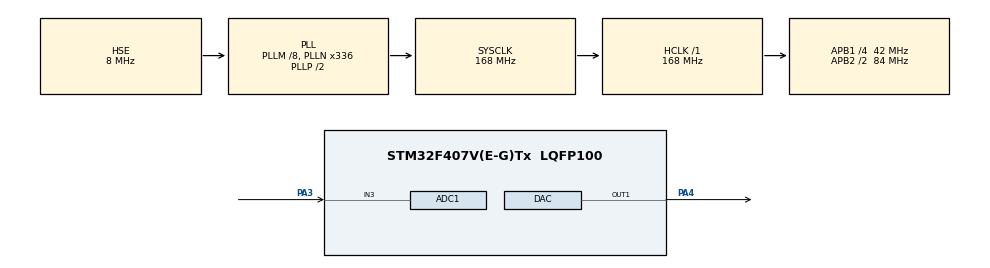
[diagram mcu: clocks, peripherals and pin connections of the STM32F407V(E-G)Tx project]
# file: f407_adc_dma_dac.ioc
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ADC1.Channel-2\#ChannelRegularConversion=ADC_CHANNEL_3
ADC1.ExternalTrigConv=ADC_EXTERNALTRIGCONV_T2_TRGO
ADC1.NbrOfConversionFlag=1
ADC1.Rank-2\#ChannelRegularConversion=1
ADC1.SamplingTime-2\#ChannelRegularConversion=ADC_SAMPLETIME_3CYCLES
ADC1.master=1
DAC.DAC_Trigger=DAC_TRIGGER_T2_TRGO
Dma.ADC1.0.Direction=DMA_PERIPH_TO_MEMORY
Dma.ADC1.0.FIFOMode=DMA_FIFOMODE_DISABLE
Dma.ADC1.0.Instance=DMA2_Stream0
Dma.ADC1.0.MemDataAlignment=DMA_MDATAALIGN_WORD
Dma.ADC1.0.MemInc=DMA_MINC_ENABLE
Dma.ADC1.0.Mode=DMA_CIRCULAR
Dma.ADC1.0.PeriphDataAlignment=DMA_PDATAALIGN_WORD
Dma.ADC1.0.PeriphInc=DMA_PINC_DISABLE
Dma.ADC1.0.Priority=DMA_PRIORITY_HIGH
Dma.DAC1.1.Direction=DMA_MEMORY_TO_PERIPH
Dma.DAC1.1.FIFOMode=DMA_FIFOMODE_DISABLE
Dma.DAC1.1.Instance=DMA1_Stream5
Dma.DAC1.1.MemDataAlignment=DMA_MDATAALIGN_WORD
Dma.DAC1.1.MemInc=DMA_MINC_ENABLE
Dma.DAC1.1.Mode=DMA_CIRCULAR
Dma.DAC1.1.PeriphDataAlignment=DMA_PDATAALIGN_WORD
Dma.DAC1.1.PeriphInc=DMA_PINC_DISABLE
Dma.DAC1.1.Priority=DMA_PRIORITY_LOW
Dma.Request0=ADC1
Dma.Request1=DAC1
Mcu.Family=STM32F4
Mcu.Name=STM32F407V(E-G)Tx
Mcu.Package=LQFP100
NVIC.DMA1_Stream5_IRQn=true\:0\:0\:false\:false\:true\:false\:true
NVIC.DMA2_Stream0_IRQn=true\:0\:0\:false\:false\:true\:false\:true
NVIC.PriorityGroup=NVIC_PRIORITYGROUP_4
PA13.Mode=Serial_Wire
PA13.Signal=SYS_JTMS-SWDIO
PA14.Mode=Serial_Wire
PA14.Signal=SYS_JTCK-SWCLK
PA3.Signal=ADCx_IN3
PA4.Signal=COMP_DAC1_group
PB3.Signal=SYS_JTDO-SWO
PH0-OSC_IN.Mode=HSE-External-Oscillator
PH0-OSC_IN.Signal=RCC_OSC_IN
PH1-OSC_OUT.Mode=HSE-External-Oscillator
PH1-OSC_OUT.Signal=RCC_OSC_OUT
ProjectManager.HeapSize=0x200
ProjectManager.StackSize=0x400
ProjectManager.TargetToolchain=STM32CubeIDE
RCC.48MHZClocksFreq_Value=84000000
RCC.AHBFreq_Value=168000000
RCC.APB1CLKDivider=RCC_HCLK_DIV4
RCC.APB1Freq_Value=42000000
RCC.APB1TimFreq_Value=84000000
RCC.APB2CLKDivider=RCC_HCLK_DIV2
RCC.APB2Freq_Value=84000000
RCC.APB2TimFreq_Value=168000000
RCC.CortexFreq_Value=168000000
RCC.HCLKFreq_Value=168000000
RCC.HSE_VALUE=8000000
RCC.HSI_VALUE=16000000
RCC.LSE_VALUE=32768
RCC.PLLM=8
RCC.PLLN=336
RCC.PLLSourceVirtual=RCC_PLLSOURCE_HSE
RCC.SYSCLKFreq_VALUE=168000000
RCC.SYSCLKSource=RCC_SYSCLKSOURCE_PLLCLK
RCC.VCOOutputFreq_Value=336000000
SH.ADCx_IN3.0=ADC1_IN3,IN3
SH.COMP_DAC1_group.0=DAC_OUT1,DAC_OUT1
TIM2.Period=3499
TIM2.TIM_MasterOutputTrigger=TIM_TRGO_UPDATE
VP_TIM2_VS_ClockSourceINT.Mode=Internal
board=custom

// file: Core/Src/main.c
/* USER CODE BEGIN Header */
/**
  ******************************************************************************
  * @file           : main.c
  * @brief          : Main program body
  ******************************************************************************
  * @attention
  *
  * <h2><center>&copy; Copyright (c) 2021 STMicroelectronics.
  * All rights reserved.</center></h2>
  *
  * This software component is licensed by ST under BSD 3-Clause license,
  * the "License"; You may not use this file except in compliance with the
  * License. You may obtain a copy of the License at:
  *                        opensource.org/licenses/BSD-3-Clause
  *
  ******************************************************************************
  */

// ADC to DAC data transfer via DMA on STM32F407VGT6
// Both ADC and DAC are triggered by TIM2, configured for a sampling frequency of 24kHz
// Credits : https://www.youtube.com/watch?v=ThFfI-JSv2Y
// Note that the code shown in this tutorial video requires a couple of fixes, implemented here :
// 1. The ADC and DAC DMAs are started simultaneously, so the input and output buffer pointers
// need to be at the same location in input and output DMA buffers.
// 2. The process_data() function should not be called continuously. It needs to be triggered
// by a flag set in the dma_conv_half_complete() and dma_conv_complete() callbacks.

/* USER CODE END Header */
#include "main.h"
#include "adc.h"
#include "dac.h"
#include "dma.h"
#include "tim.h"
#include "gpio.h"

/* USER CODE BEGIN PV */

// DMA transfer block size
#define DMA_TRANSFER_SIZE 128

static uint32_t ADC_Buffer[DMA_TRANSFER_SIZE*2];
static uint32_t DAC_Buffer[DMA_TRANSFER_SIZE*2];

static volatile uint32_t* PtrInBuf;
static volatile uint32_t* PtrOutBuf;

static volatile int ProcessDataFlag = 0;
/* USER CODE END PV */

void SystemClock_Config(void);
/* USER CODE BEGIN PFP */
static void process_data();

/* USER CODE END PFP */

int main(void)
{

  /* MCU Configuration--------------------------------------------------------*/

  /* Reset of all peripherals, Initializes the Flash interface and the Systick. */
  HAL_Init();

  /* Configure the system clock */
  SystemClock_Config();

  /* Initialize all configured peripherals */
  MX_GPIO_Init();
  MX_DMA_Init();
  MX_ADC1_Init();
  MX_DAC_Init();
  MX_TIM2_Init();
  /* USER CODE BEGIN 2 */
  HAL_TIM_Base_Start(&htim2);
  HAL_ADC_Start_DMA(&hadc1, ADC_Buffer, DMA_TRANSFER_SIZE*2);
  HAL_DAC_Start_DMA(&hdac, DAC_CHANNEL_1, DAC_Buffer, DMA_TRANSFER_SIZE*2, DAC_ALIGN_12B_R);
  /* USER CODE END 2 */

  /* Infinite loop */
  while (1)
  {

    /* USER CODE BEGIN 3 */
	  if (ProcessDataFlag) {
		  ProcessDataFlag = 0;
		  process_data();
	  	  }
  }
  /* USER CODE END 3 */
}

void SystemClock_Config(void)
{
  RCC_OscInitTypeDef RCC_OscInitStruct = {0};
  RCC_ClkInitTypeDef RCC_ClkInitStruct = {0};

  /** Configure the main internal regulator output voltage
  */
  __HAL_RCC_PWR_CLK_ENABLE();
  __HAL_PWR_VOLTAGESCALING_CONFIG(PWR_REGULATOR_VOLTAGE_SCALE1);
  /** Initializes the RCC Oscillators according to the specified parameters
  * in the RCC_OscInitTypeDef structure.
  */
  RCC_OscInitStruct.OscillatorType = RCC_OSCILLATORTYPE_HSE;
  RCC_OscInitStruct.HSEState = RCC_HSE_ON;
  RCC_OscInitStruct.PLL.PLLState = RCC_PLL_ON;
  RCC_OscInitStruct.PLL.PLLSource = RCC_PLLSOURCE_HSE;
  RCC_OscInitStruct.PLL.PLLM = 8;
  RCC_OscInitStruct.PLL.PLLN = 336;
  RCC_OscInitStruct.PLL.PLLP = RCC_PLLP_DIV2;
  RCC_OscInitStruct.PLL.PLLQ = 4;
  if (HAL_RCC_OscConfig(&RCC_OscInitStruct) != HAL_OK)
  {
    Error_Handler();
  }
  /** Initializes the CPU, AHB and APB buses clocks
  */
  RCC_ClkInitStruct.ClockType = RCC_CLOCKTYPE_HCLK|RCC_CLOCKTYPE_SYSCLK
                              |RCC_CLOCKTYPE_PCLK1|RCC_CLOCKTYPE_PCLK2;
  RCC_ClkInitStruct.SYSCLKSource = RCC_SYSCLKSOURCE_PLLCLK;
  RCC_ClkInitStruct.AHBCLKDivider = RCC_SYSCLK_DIV1;
  RCC_ClkInitStruct.APB1CLKDivider = RCC_HCLK_DIV4;
  RCC_ClkInitStruct.APB2CLKDivider = RCC_HCLK_DIV2;

  if (HAL_RCC_ClockConfig(&RCC_ClkInitStruct, FLASH_LATENCY_5) != HAL_OK)
  {
    Error_Handler();
  }
}

/* USER CODE BEGIN 4 */
void HAL_ADC_ConvCpltCallback(ADC_HandleTypeDef* hadc){
	// second half of ADC_Buffer is full
	PtrInBuf = (volatile uint32_t*)&ADC_Buffer[DMA_TRANSFER_SIZE];
	PtrOutBuf = (volatile uint32_t*)&DAC_Buffer[DMA_TRANSFER_SIZE];
	ProcessDataFlag = 1;
}

void HAL_ADC_ConvHalfCpltCallback(ADC_HandleTypeDef* hadc){
	// first half of ADC_Buffer is full
	PtrInBuf = (volatile uint32_t*)&ADC_Buffer[0];
	PtrOutBuf = (volatile uint32_t*)&DAC_Buffer[0];
	ProcessDataFlag = 1;
}

static void process_data(){
	for (int inx = 0; inx < DMA_TRANSFER_SIZE; inx++) {
		PtrOutBuf[inx] = PtrInBuf[inx]/2;
		}
	}
/* USER CODE END 4 */

void Error_Handler(void)
{
  __disable_irq();
  while (1)
  {
  }
}

/************************ (C) COPYRIGHT STMicroelectronics *****END OF FILE****/
